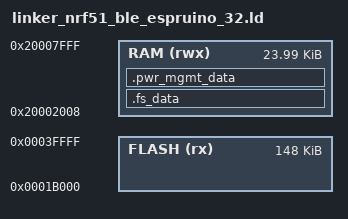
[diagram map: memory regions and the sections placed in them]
/* Linker script to configure memory regions. */

SEARCH_DIR(.)
GROUP(-lgcc -lc -lnosys)

MEMORY
{
  FLASH (rx) : ORIGIN = 0x1b000, LENGTH = 0x25000
  RAM (rwx) :  ORIGIN = 0x20002008, LENGTH = 0x5FF8
}

SECTIONS
{
  .fs_data :
  {
    PROVIDE(__start_fs_data = .);
    KEEP(*(.fs_data))
    PROVIDE(__stop_fs_data = .);
  } > RAM
  .pwr_mgmt_data :
  {
    PROVIDE(__start_pwr_mgmt_data = .);
    KEEP(*(.pwr_mgmt_data))
    PROVIDE(__stop_pwr_mgmt_data = .);
  } > RAM
} INSERT AFTER .data;

INCLUDE "gcc_nrf5x_espruino_common.ld"
